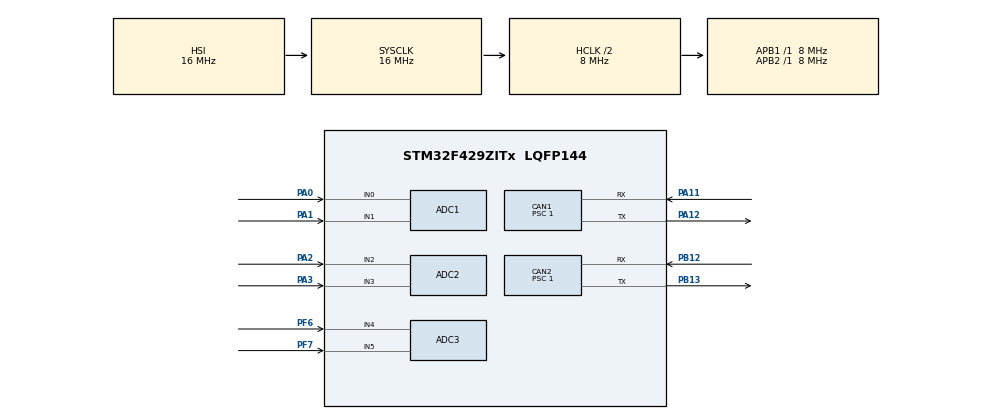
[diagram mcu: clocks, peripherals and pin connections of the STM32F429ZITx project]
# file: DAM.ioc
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ADC1.Channel-0\#ChannelRegularConversion=ADC_CHANNEL_0
ADC1.ClockPrescaler=ADC_CLOCK_SYNC_PCLK_DIV4
ADC1.ContinuousConvMode=ENABLE
ADC1.DMAContinuousRequests=ENABLE
ADC1.EOCSelection=ADC_EOC_SEQ_CONV
ADC1.NbrOfConversionFlag=1
ADC1.Rank-0\#ChannelRegularConversion=1
ADC1.SamplingTime-0\#ChannelRegularConversion=ADC_SAMPLETIME_3CYCLES
ADC1.master=1
ADC2.Channel-1\#ChannelRegularConversion=ADC_CHANNEL_2
ADC2.ClockPrescaler=ADC_CLOCK_SYNC_PCLK_DIV4
ADC2.ContinuousConvMode=ENABLE
ADC2.DMAContinuousRequests=ENABLE
ADC2.EOCSelection=ADC_EOC_SEQ_CONV
ADC2.NbrOfConversionFlag=1
ADC2.Rank-1\#ChannelRegularConversion=1
ADC2.SamplingTime-1\#ChannelRegularConversion=ADC_SAMPLETIME_3CYCLES
ADC3.Channel-1\#ChannelRegularConversion=ADC_CHANNEL_4
ADC3.ClockPrescaler=ADC_CLOCK_SYNC_PCLK_DIV4
ADC3.ContinuousConvMode=ENABLE
ADC3.DMAContinuousRequests=ENABLE
ADC3.EOCSelection=ADC_EOC_SEQ_CONV
ADC3.NbrOfConversionFlag=1
ADC3.Rank-1\#ChannelRegularConversion=1
ADC3.SamplingTime-1\#ChannelRegularConversion=ADC_SAMPLETIME_3CYCLES
CAN1.BS1=CAN_BS1_6TQ
CAN1.CalculateTimeQuantum=125.0
CAN1.Prescaler=1
CAN2.BS1=CAN_BS1_6TQ
CAN2.CalculateTimeQuantum=125.0
CAN2.Prescaler=1
Dma.ADC1.0.Direction=DMA_PERIPH_TO_MEMORY
Dma.ADC1.0.FIFOMode=DMA_FIFOMODE_DISABLE
Dma.ADC1.0.Instance=DMA2_Stream0
Dma.ADC1.0.MemDataAlignment=DMA_MDATAALIGN_HALFWORD
Dma.ADC1.0.MemInc=DMA_MINC_ENABLE
Dma.ADC1.0.Mode=DMA_NORMAL
Dma.ADC1.0.PeriphDataAlignment=DMA_PDATAALIGN_HALFWORD
Dma.ADC1.0.PeriphInc=DMA_PINC_DISABLE
Dma.ADC1.0.Priority=DMA_PRIORITY_HIGH
Dma.ADC2.1.Direction=DMA_PERIPH_TO_MEMORY
Dma.ADC2.1.FIFOMode=DMA_FIFOMODE_DISABLE
Dma.ADC2.1.Instance=DMA2_Stream2
Dma.ADC2.1.MemDataAlignment=DMA_MDATAALIGN_HALFWORD
Dma.ADC2.1.MemInc=DMA_MINC_ENABLE
Dma.ADC2.1.Mode=DMA_NORMAL
Dma.ADC2.1.PeriphDataAlignment=DMA_PDATAALIGN_HALFWORD
Dma.ADC2.1.PeriphInc=DMA_PINC_DISABLE
Dma.ADC2.1.Priority=DMA_PRIORITY_HIGH
Dma.ADC3.2.Direction=DMA_PERIPH_TO_MEMORY
Dma.ADC3.2.FIFOMode=DMA_FIFOMODE_DISABLE
Dma.ADC3.2.Instance=DMA2_Stream1
Dma.ADC3.2.MemDataAlignment=DMA_MDATAALIGN_HALFWORD
Dma.ADC3.2.MemInc=DMA_MINC_ENABLE
Dma.ADC3.2.Mode=DMA_NORMAL
Dma.ADC3.2.PeriphDataAlignment=DMA_PDATAALIGN_HALFWORD
Dma.ADC3.2.PeriphInc=DMA_PINC_DISABLE
Dma.ADC3.2.Priority=DMA_PRIORITY_HIGH
Dma.Request0=ADC1
Dma.Request1=ADC2
Dma.Request2=ADC3
FREERTOS.Tasks01=MainTask,24,128,StartMainTask,Default,NULL,Dynamic,NULL,NULL;gcanTxTask,24,128,gopherCAN_tx_task,Default,NULL,Dynamic,NULL,NULL;gcan_rx_buf,24,128,gcan_rx_buffer_service_task,Default,NULL,Dynamic,NULL,NULL
Mcu.Family=STM32F4
Mcu.Name=STM32F429ZITx
Mcu.Package=LQFP144
NVIC.ADC_IRQn=true\:5\:0\:false\:false\:true\:true\:true\:true
NVIC.CAN1_RX0_IRQn=true\:5\:0\:false\:false\:true\:true\:true\:true
NVIC.CAN1_RX1_IRQn=true\:5\:0\:false\:false\:true\:true\:true\:true
NVIC.CAN1_TX_IRQn=true\:5\:0\:false\:false\:true\:true\:true\:true
NVIC.CAN2_RX0_IRQn=true\:5\:0\:false\:false\:true\:true\:true\:true
NVIC.CAN2_RX1_IRQn=true\:5\:0\:false\:false\:true\:true\:true\:true
NVIC.DMA2_Stream0_IRQn=true\:5\:0\:false\:false\:true\:true\:false\:true
NVIC.DMA2_Stream1_IRQn=true\:5\:0\:false\:false\:true\:true\:false\:true
NVIC.DMA2_Stream2_IRQn=true\:5\:0\:false\:false\:true\:true\:false\:true
NVIC.PriorityGroup=NVIC_PRIORITYGROUP_4
NVIC.TIM1_TRG_COM_TIM11_IRQn=true\:5\:0\:false\:false\:true\:true\:true\:true
NVIC.TIM1_UP_TIM10_IRQn=true\:5\:0\:false\:false\:true\:true\:true\:true
NVIC.TIM8_TRG_COM_TIM14_IRQn=true\:0\:0\:false\:false\:true\:false\:false\:true
NVIC.TIM8_UP_TIM13_IRQn=true\:5\:0\:false\:false\:true\:true\:true\:true
NVIC.TimeBase=TIM8_TRG_COM_TIM14_IRQn
NVIC.TimeBaseIP=TIM14
PA0/WKUP.Signal=ADCx_IN0
PA1.Signal=ADCx_IN1
PA11.GPIO_PuPd=GPIO_PULLUP
PA11.Mode=Master
PA11.Signal=CAN1_RX
PA12.GPIO_PuPd=GPIO_PULLUP
PA12.Mode=Master
PA12.Signal=CAN1_TX
PA2.Signal=ADCx_IN2
PA3.Signal=ADCx_IN3
PB12.GPIO_PuPd=GPIO_PULLUP
PB12.Mode=Slave
PB12.Signal=CAN2_RX
PB13.GPIO_PuPd=GPIO_PULLUP
PB13.Mode=Slave
PB13.Signal=CAN2_TX
PC14/OSC32_IN.Mode=LSE-External-Oscillator
PC14/OSC32_IN.Signal=RCC_OSC32_IN
PC15/OSC32_OUT.Mode=LSE-External-Oscillator
PC15/OSC32_OUT.Signal=RCC_OSC32_OUT
PF6.Mode=IN4
PF6.Signal=ADC3_IN4
PF7.Mode=IN5
PF7.Signal=ADC3_IN5
PH0/OSC_IN.Mode=HSE-External-Clock-Source
PH0/OSC_IN.Signal=RCC_OSC_IN
PH1/OSC_OUT.Mode=HSE-External-Clock-Source
PH1/OSC_OUT.Signal=RCC_OSC_OUT
ProjectManager.HeapSize=0x200
ProjectManager.StackSize=0x400
ProjectManager.TargetToolchain=STM32CubeIDE
RCC.AHBCLKDivider=RCC_SYSCLK_DIV2
RCC.AHBFreq_Value=8000000
RCC.APB1Freq_Value=8000000
RCC.APB1TimFreq_Value=8000000
RCC.APB2Freq_Value=8000000
RCC.APB2TimFreq_Value=8000000
RCC.CortexFreq_Value=8000000
RCC.HCLKFreq_Value=8000000
RCC.HSE_VALUE=25000000
RCC.HSI_VALUE=16000000
RCC.SYSCLKFreq_VALUE=16000000
RCC.VCOOutputFreq_Value=192000000
SH.ADCx_IN0.0=ADC1_IN0,IN0
SH.ADCx_IN1.0=ADC1_IN1,IN1
SH.ADCx_IN2.0=ADC2_IN2,IN2
SH.ADCx_IN3.0=ADC2_IN3,IN3
VP_FREERTOS_VS_CMSIS_V2.Mode=CMSIS_V2
VP_SYS_VS_tim14.Mode=TIM14
VP_TIM10_VS_ClockSourceINT.Mode=Enable_Timer
VP_TIM11_VS_ClockSourceINT.Mode=Enable_Timer
VP_TIM13_VS_ClockSourceINT.Mode=Enable_Timer
board=custom

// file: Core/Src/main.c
/* USER CODE BEGIN Header */
/**
  ******************************************************************************
  * @file           : main.c
  * @brief          : Main program body
  ******************************************************************************
  * @attention
  *
  * <h2><center>&copy; Copyright (c) 2021 STMicroelectronics.
  * All rights reserved.</center></h2>
  *
  * This software component is licensed by ST under BSD 3-Clause license,
  * the "License"; You may not use this file except in compliance with the
  * License. You may obtain a copy of the License at:
  *                        opensource.org/licenses/BSD-3-Clause
  *
  ******************************************************************************
  */
/* USER CODE END Header */

#include "main.h"
#include "cmsis_os.h"

/* USER CODE BEGIN Includes */
#include "DAM.h"

/* USER CODE END Includes */

ADC_HandleTypeDef hadc1;
ADC_HandleTypeDef hadc2;
ADC_HandleTypeDef hadc3;
DMA_HandleTypeDef hdma_adc1;
DMA_HandleTypeDef hdma_adc2;
DMA_HandleTypeDef hdma_adc3;

CAN_HandleTypeDef hcan1;
CAN_HandleTypeDef hcan2;

TIM_HandleTypeDef htim10;
TIM_HandleTypeDef htim11;
TIM_HandleTypeDef htim13;

/* Definitions for MainTask */
osThreadId_t MainTaskHandle;
const osThreadAttr_t MainTask_attributes = {
  .name = "MainTask",
  .priority = (osPriority_t) osPriorityNormal,
  .stack_size = 128 * 4
};
/* Definitions for gcanTxTask */
osThreadId_t gcanTxTaskHandle;
const osThreadAttr_t gcanTxTask_attributes = {
  .name = "gcanTxTask",
  .priority = (osPriority_t) osPriorityNormal,
  .stack_size = 128 * 4
};
/* Definitions for gcan_rx_buf */
osThreadId_t gcan_rx_bufHandle;
const osThreadAttr_t gcan_rx_buf_attributes = {
  .name = "gcan_rx_buf",
  .priority = (osPriority_t) osPriorityNormal,
  .stack_size = 128 * 4
};

void SystemClock_Config(void);
static void MX_GPIO_Init(void);
static void MX_DMA_Init(void);
static void MX_ADC1_Init(void);
static void MX_ADC2_Init(void);
static void MX_ADC3_Init(void);
static void MX_CAN1_Init(void);
static void MX_CAN2_Init(void);
static void MX_TIM10_Init(void);
static void MX_TIM11_Init(void);
static void MX_TIM13_Init(void);
void StartMainTask(void *argument);
void gopherCAN_tx_task(void *argument);
void gcan_rx_buffer_service_task(void *argument);

int main(void)
{

  /* MCU Configuration--------------------------------------------------------*/

  /* Reset of all peripherals, Initializes the Flash interface and the Systick. */
  HAL_Init();

  /* Configure the system clock */
  SystemClock_Config();

  /* Initialize all configured peripherals */
  MX_GPIO_Init();
  MX_DMA_Init();
  MX_ADC1_Init();
  MX_ADC2_Init();
  MX_ADC3_Init();
  MX_CAN1_Init();
  MX_CAN2_Init();
  MX_TIM10_Init();
  MX_TIM11_Init();
  MX_TIM13_Init();
  /* USER CODE BEGIN 2 */

  // Library Init
  DAM_init();

  /* USER CODE END 2 */

  /* Init scheduler */
  osKernelInitialize();

  /* Create the thread(s) */
  /* creation of MainTask */
  MainTaskHandle = osThreadNew(StartMainTask, NULL, &MainTask_attributes);

  /* creation of gcanTxTask */
  gcanTxTaskHandle = osThreadNew(gopherCAN_tx_task, NULL, &gcanTxTask_attributes);

  /* creation of gcan_rx_buf */
  gcan_rx_bufHandle = osThreadNew(gcan_rx_buffer_service_task, NULL, &gcan_rx_buf_attributes);

  /* Start scheduler */
  osKernelStart();

  /* We should never get here as control is now taken by the scheduler */
  /* Infinite loop */
  while (1)
  {

  }
}

void SystemClock_Config(void)
{
  RCC_OscInitTypeDef RCC_OscInitStruct = {0};
  RCC_ClkInitTypeDef RCC_ClkInitStruct = {0};

  /** Configure the main internal regulator output voltage
  */
  __HAL_RCC_PWR_CLK_ENABLE();
  __HAL_PWR_VOLTAGESCALING_CONFIG(PWR_REGULATOR_VOLTAGE_SCALE3);
  /** Initializes the CPU, AHB and APB busses clocks
  */
  RCC_OscInitStruct.OscillatorType = RCC_OSCILLATORTYPE_HSI;
  RCC_OscInitStruct.HSIState = RCC_HSI_ON;
  RCC_OscInitStruct.HSICalibrationValue = RCC_HSICALIBRATION_DEFAULT;
  RCC_OscInitStruct.PLL.PLLState = RCC_PLL_NONE;
  if (HAL_RCC_OscConfig(&RCC_OscInitStruct) != HAL_OK)
  {
    Error_Handler();
  }
  /** Initializes the CPU, AHB and APB busses clocks
  */
  RCC_ClkInitStruct.ClockType = RCC_CLOCKTYPE_HCLK|RCC_CLOCKTYPE_SYSCLK
                              |RCC_CLOCKTYPE_PCLK1|RCC_CLOCKTYPE_PCLK2;
  RCC_ClkInitStruct.SYSCLKSource = RCC_SYSCLKSOURCE_HSI;
  RCC_ClkInitStruct.AHBCLKDivider = RCC_SYSCLK_DIV2;
  RCC_ClkInitStruct.APB1CLKDivider = RCC_HCLK_DIV1;
  RCC_ClkInitStruct.APB2CLKDivider = RCC_HCLK_DIV1;

  if (HAL_RCC_ClockConfig(&RCC_ClkInitStruct, FLASH_LATENCY_0) != HAL_OK)
  {
    Error_Handler();
  }
}

static void MX_ADC1_Init(void)
{

  ADC_ChannelConfTypeDef sConfig = {0};

  /** Configure the global features of the ADC (Clock, Resolution, Data Alignment and number of conversion)
  */
  hadc1.Instance = ADC1;
  hadc1.Init.ClockPrescaler = ADC_CLOCK_SYNC_PCLK_DIV4;
  hadc1.Init.Resolution = ADC_RESOLUTION_12B;
  hadc1.Init.ScanConvMode = DISABLE;
  hadc1.Init.ContinuousConvMode = ENABLE;
  hadc1.Init.DiscontinuousConvMode = DISABLE;
  hadc1.Init.ExternalTrigConvEdge = ADC_EXTERNALTRIGCONVEDGE_NONE;
  hadc1.Init.ExternalTrigConv = ADC_SOFTWARE_START;
  hadc1.Init.DataAlign = ADC_DATAALIGN_RIGHT;
  hadc1.Init.NbrOfConversion = 1;
  hadc1.Init.DMAContinuousRequests = ENABLE;
  hadc1.Init.EOCSelection = ADC_EOC_SEQ_CONV;
  if (HAL_ADC_Init(&hadc1) != HAL_OK)
  {
    Error_Handler();
  }
  /** Configure for the selected ADC regular channel its corresponding rank in the sequencer and its sample time.
  */
  sConfig.Channel = ADC_CHANNEL_0;
  sConfig.Rank = 1;
  sConfig.SamplingTime = ADC_SAMPLETIME_3CYCLES;
  if (HAL_ADC_ConfigChannel(&hadc1, &sConfig) != HAL_OK)
  {
    Error_Handler();
  }

}

static void MX_ADC2_Init(void)
{

  ADC_ChannelConfTypeDef sConfig = {0};

  /** Configure the global features of the ADC (Clock, Resolution, Data Alignment and number of conversion)
  */
  hadc2.Instance = ADC2;
  hadc2.Init.ClockPrescaler = ADC_CLOCK_SYNC_PCLK_DIV4;
  hadc2.Init.Resolution = ADC_RESOLUTION_12B;
  hadc2.Init.ScanConvMode = DISABLE;
  hadc2.Init.ContinuousConvMode = ENABLE;
  hadc2.Init.DiscontinuousConvMode = DISABLE;
  hadc2.Init.ExternalTrigConvEdge = ADC_EXTERNALTRIGCONVEDGE_NONE;
  hadc2.Init.ExternalTrigConv = ADC_SOFTWARE_START;
  hadc2.Init.DataAlign = ADC_DATAALIGN_RIGHT;
  hadc2.Init.NbrOfConversion = 1;
  hadc2.Init.DMAContinuousRequests = ENABLE;
  hadc2.Init.EOCSelection = ADC_EOC_SEQ_CONV;
  if (HAL_ADC_Init(&hadc2) != HAL_OK)
  {
    Error_Handler();
  }
  /** Configure for the selected ADC regular channel its corresponding rank in the sequencer and its sample time.
  */
  sConfig.Channel = ADC_CHANNEL_2;
  sConfig.Rank = 1;
  sConfig.SamplingTime = ADC_SAMPLETIME_3CYCLES;
  if (HAL_ADC_ConfigChannel(&hadc2, &sConfig) != HAL_OK)
  {
    Error_Handler();
  }

}

static void MX_ADC3_Init(void)
{

  ADC_ChannelConfTypeDef sConfig = {0};

  /** Configure the global features of the ADC (Clock, Resolution, Data Alignment and number of conversion)
  */
  hadc3.Instance = ADC3;
  hadc3.Init.ClockPrescaler = ADC_CLOCK_SYNC_PCLK_DIV4;
  hadc3.Init.Resolution = ADC_RESOLUTION_12B;
  hadc3.Init.ScanConvMode = DISABLE;
  hadc3.Init.ContinuousConvMode = ENABLE;
  hadc3.Init.DiscontinuousConvMode = DISABLE;
  hadc3.Init.ExternalTrigConvEdge = ADC_EXTERNALTRIGCONVEDGE_NONE;
  hadc3.Init.ExternalTrigConv = ADC_SOFTWARE_START;
  hadc3.Init.DataAlign = ADC_DATAALIGN_RIGHT;
  hadc3.Init.NbrOfConversion = 1;
  hadc3.Init.DMAContinuousRequests = ENABLE;
  hadc3.Init.EOCSelection = ADC_EOC_SEQ_CONV;
  if (HAL_ADC_Init(&hadc3) != HAL_OK)
  {
    Error_Handler();
  }
  /** Configure for the selected ADC regular channel its corresponding rank in the sequencer and its sample time.
  */
  sConfig.Channel = ADC_CHANNEL_4;
  sConfig.Rank = 1;
  sConfig.SamplingTime = ADC_SAMPLETIME_3CYCLES;
  if (HAL_ADC_ConfigChannel(&hadc3, &sConfig) != HAL_OK)
  {
    Error_Handler();
  }

}

static void MX_CAN1_Init(void)
{

  hcan1.Instance = CAN1;
  hcan1.Init.Prescaler = 1;
  hcan1.Init.Mode = CAN_MODE_NORMAL;
  hcan1.Init.SyncJumpWidth = CAN_SJW_1TQ;
  hcan1.Init.TimeSeg1 = CAN_BS1_6TQ;
  hcan1.Init.TimeSeg2 = CAN_BS2_1TQ;
  hcan1.Init.TimeTriggeredMode = DISABLE;
  hcan1.Init.AutoBusOff = DISABLE;
  hcan1.Init.AutoWakeUp = DISABLE;
  hcan1.Init.AutoRetransmission = DISABLE;
  hcan1.Init.ReceiveFifoLocked = DISABLE;
  hcan1.Init.TransmitFifoPriority = DISABLE;
  if (HAL_CAN_Init(&hcan1) != HAL_OK)
  {
    Error_Handler();
  }

}

static void MX_CAN2_Init(void)
{

  hcan2.Instance = CAN2;
  hcan2.Init.Prescaler = 1;
  hcan2.Init.Mode = CAN_MODE_NORMAL;
  hcan2.Init.SyncJumpWidth = CAN_SJW_1TQ;
  hcan2.Init.TimeSeg1 = CAN_BS1_6TQ;
  hcan2.Init.TimeSeg2 = CAN_BS2_1TQ;
  hcan2.Init.TimeTriggeredMode = DISABLE;
  hcan2.Init.AutoBusOff = DISABLE;
  hcan2.Init.AutoWakeUp = DISABLE;
  hcan2.Init.AutoRetransmission = DISABLE;
  hcan2.Init.ReceiveFifoLocked = DISABLE;
  hcan2.Init.TransmitFifoPriority = DISABLE;
  if (HAL_CAN_Init(&hcan2) != HAL_OK)
  {
    Error_Handler();
  }

}

static void MX_TIM10_Init(void)
{

  htim10.Instance = TIM10;
  htim10.Init.Prescaler = 0;
  htim10.Init.CounterMode = TIM_COUNTERMODE_UP;
  htim10.Init.Period = 0;
  htim10.Init.ClockDivision = TIM_CLOCKDIVISION_DIV1;
  htim10.Init.AutoReloadPreload = TIM_AUTORELOAD_PRELOAD_DISABLE;
  if (HAL_TIM_Base_Init(&htim10) != HAL_OK)
  {
    Error_Handler();
  }

}

static void MX_TIM11_Init(void)
{

  htim11.Instance = TIM11;
  htim11.Init.Prescaler = 0;
  htim11.Init.CounterMode = TIM_COUNTERMODE_UP;
  htim11.Init.Period = 0;
  htim11.Init.ClockDivision = TIM_CLOCKDIVISION_DIV1;
  htim11.Init.AutoReloadPreload = TIM_AUTORELOAD_PRELOAD_DISABLE;
  if (HAL_TIM_Base_Init(&htim11) != HAL_OK)
  {
    Error_Handler();
  }

}

static void MX_TIM13_Init(void)
{

  htim13.Instance = TIM13;
  htim13.Init.Prescaler = 0;
  htim13.Init.CounterMode = TIM_COUNTERMODE_UP;
  htim13.Init.Period = 0;
  htim13.Init.ClockDivision = TIM_CLOCKDIVISION_DIV1;
  htim13.Init.AutoReloadPreload = TIM_AUTORELOAD_PRELOAD_DISABLE;
  if (HAL_TIM_Base_Init(&htim13) != HAL_OK)
  {
    Error_Handler();
  }

}

static void MX_DMA_Init(void)
{

  /* DMA controller clock enable */
  __HAL_RCC_DMA2_CLK_ENABLE();

  /* DMA interrupt init */
  /* DMA2_Stream0_IRQn interrupt configuration */
  HAL_NVIC_SetPriority(DMA2_Stream0_IRQn, 5, 0);
  HAL_NVIC_EnableIRQ(DMA2_Stream0_IRQn);
  /* DMA2_Stream1_IRQn interrupt configuration */
  HAL_NVIC_SetPriority(DMA2_Stream1_IRQn, 5, 0);
  HAL_NVIC_EnableIRQ(DMA2_Stream1_IRQn);
  /* DMA2_Stream2_IRQn interrupt configuration */
  HAL_NVIC_SetPriority(DMA2_Stream2_IRQn, 5, 0);
  HAL_NVIC_EnableIRQ(DMA2_Stream2_IRQn);

}

static void MX_GPIO_Init(void)
{

  /* GPIO Ports Clock Enable */
  __HAL_RCC_GPIOC_CLK_ENABLE();
  __HAL_RCC_GPIOF_CLK_ENABLE();
  __HAL_RCC_GPIOH_CLK_ENABLE();
  __HAL_RCC_GPIOA_CLK_ENABLE();
  __HAL_RCC_GPIOB_CLK_ENABLE();

}

void StartMainTask(void *argument)
{
  /* USER CODE BEGIN 5 */
  /* Infinite loop */
  for(;;)
  {
      DAM_main_task();
      // Should never get here
      Error_Handler();
  }
  /* USER CODE END 5 */
}

void gopherCAN_tx_task(void *argument)
{
  /* USER CODE BEGIN gopherCAN_tx_task */
  /* Infinite loop */
  for(;;)
  {
    gopherCAN_tx_service_task();
    // Should never get here
    Error_Handler();
  }
  /* USER CODE END gopherCAN_tx_task */
}

void gcan_rx_buffer_service_task(void *argument)
{
  /* USER CODE BEGIN gcan_rx_buffer_service_task */
  /* Infinite loop */
  for(;;)
  {
      gopherCAN_rx_buffer_service_task();
     //should never get here
     Error_Handler();
  }
  /* USER CODE END gcan_rx_buffer_service_task */
}

 /**
  * @brief  Period elapsed callback in non blocking mode
  * @note   This function is called  when TIM14 interrupt took place, inside
  * HAL_TIM_IRQHandler(). It makes a direct call to HAL_IncTick() to increment
  * a global variable "uwTick" used as application time base.
  * @param  htim : TIM handle
  * @retval None
  */
void HAL_TIM_PeriodElapsedCallback(TIM_HandleTypeDef *htim)
{
  if (htim->Instance == TIM14) {
    HAL_IncTick();
  }
  /* USER CODE BEGIN Callback 1 */
  else
  {
      DAQ_TimerCallback(htim);
  }
  /* USER CODE END Callback 1 */
}

void Error_Handler(void)
{
  /* USER CODE BEGIN Error_Handler_Debug */
  /* User can add his own implementation to report the HAL error return state */
  // Something fucked up, handle it here
  handle_DAM_error(INITIALIZATION_ERROR);

  /* USER CODE END Error_Handler_Debug */
}

/************************ (C) COPYRIGHT STMicroelectronics *****END OF FILE****/
